# f28002x_mem_cfg_regs register map
Vendor: Texas Instruments
Peripheral module from a debugger description file (folder C2000).
Address unit: 16 bits
Registers are 32-bit, read-write, no defined reset value unless marked. A register's access mark holds for its fields unless they carry their own. Offsets are as the file gives them; lines under a group give offsets from that group; [hi:lo] are bit positions; {n}, {i} and the like mark numbered series; 'fields as' and 'values as' point back to an identical list; <NAME> marks a mode.

## MEM_CFG_REGS — MEM CFG Registers
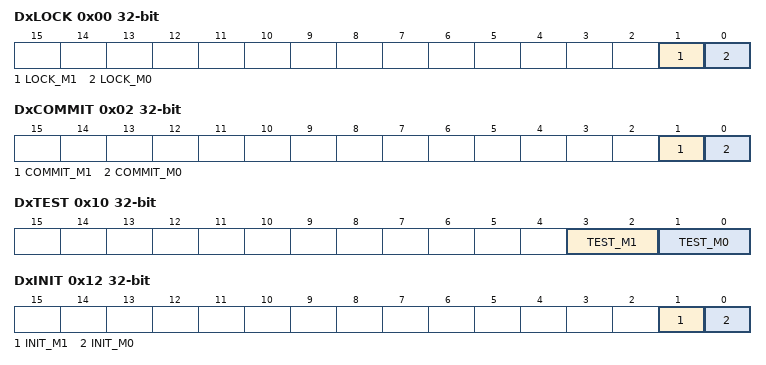
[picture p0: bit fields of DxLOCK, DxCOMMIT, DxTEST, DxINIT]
0x00 DxLOCK — Dedicated RAM Config Lock Register
  [1] LOCK_M1 — M1 RAM Lock bits
  [0] LOCK_M0 — M0 RAM Lock bits
0x02 DxCOMMIT — Dedicated RAM Config Lock Commit Register
  [1] COMMIT_M1 — M1 RAM Permanent Lock bits
  [0] COMMIT_M0 — M0 RAM Permanent Lock bits
0x10 DxTEST — Dedicated RAM TEST Register
  [3:2] TEST_M1 — Selects the different modes for M1 RAM
  [1:0] TEST_M0 — Selects the different modes for M0 RAM
0x12 DxINIT — Dedicated RAM Init Register
  [1] INIT_M1 — RAM Initialization control for M1 RAM.
  [0] INIT_M0 — RAM Initialization control for M0 RAM.
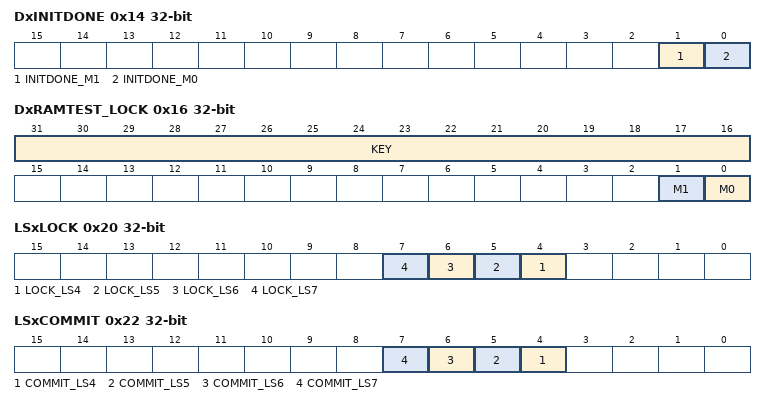
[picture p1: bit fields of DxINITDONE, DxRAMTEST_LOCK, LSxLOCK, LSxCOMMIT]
0x14 DxINITDONE ro — Dedicated RAM InitDone Status Register
  [1] INITDONE_M1 — RAM Initialization status for M1 RAM.
  [0] INITDONE_M0 — RAM Initialization status for M0 RAM.
0x16 DxRAMTEST_LOCK — Lock register to Dx RAM TEST registers
  [31:16] KEY — Key for writing DxRAMTEST_LOCK
  [1] M1 — DxTEST.TEST_M1 LOCK
  [0] M0 — DxTEST.TEST_M0 LOCK
0x20 LSxLOCK — Local Shared RAM Config Lock Register
  [n] LOCK_LS{n} (n=4..7) — LS{n} RAM Lock bits
0x22 LSxCOMMIT — Local Shared RAM Config Lock Commit Register
  [n] COMMIT_LS{n} (n=4..7) — LS{n} RAM Permanent Lock bits
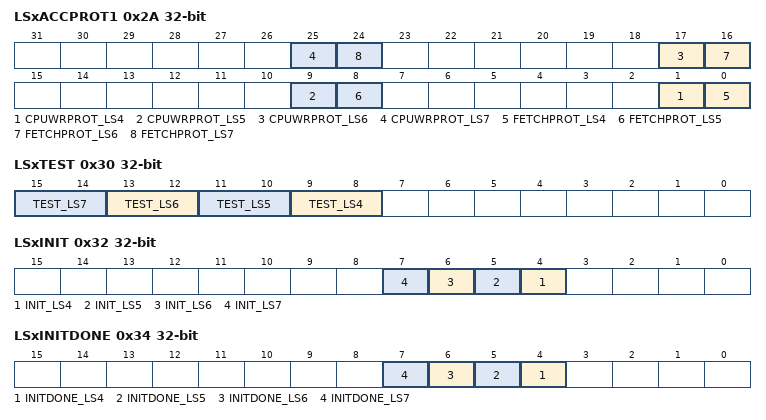
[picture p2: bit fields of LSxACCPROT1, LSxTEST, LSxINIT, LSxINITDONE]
0x2A LSxACCPROT1 — Local Shared RAM Config Register 1
  [8n-31] CPUWRPROT_LS{n} (n=4..7) — CPU WR Protection For LS{n} RAM
  [8n-32] FETCHPROT_LS{n} (n=4..7) — Fetch Protection For LS{n} RAM
0x30 LSxTEST — Local Shared RAM TEST Register
  [2n+1:2n] TEST_LS{n} (n=4..7) — Selects the different modes for LS{n} RAM
0x32 LSxINIT — Local Shared RAM Init Register
  [n] INIT_LS{n} (n=4..7) — RAM Initialization control for LS{n} RAM.
0x34 LSxINITDONE ro — Local Shared RAM InitDone Status Register
  [n] INITDONE_LS{n} (n=4..7) — RAM Initialization status for LS{n} RAM.
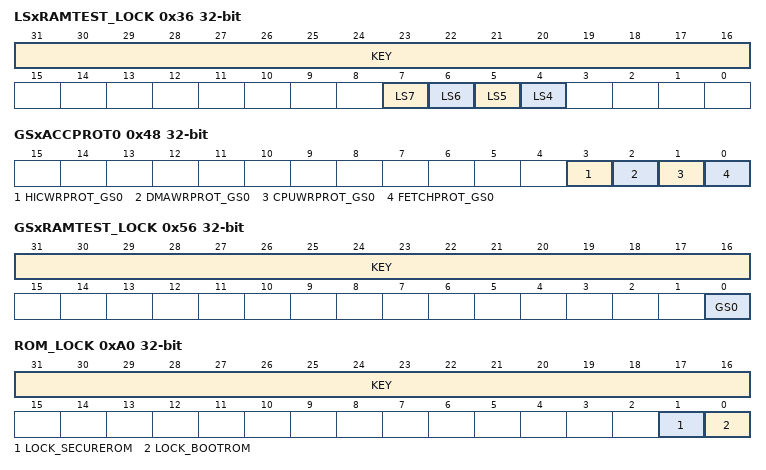
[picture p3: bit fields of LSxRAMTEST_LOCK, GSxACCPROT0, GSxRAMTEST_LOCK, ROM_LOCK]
0x36 LSxRAMTEST_LOCK — Lock register to LSx RAM TEST registers
  [31:16] KEY — KEY to enable write to lock
  [n] LS{n} (n=4..7) — LSxTEST.TEST_LS{n} LOCK
0x40 GSxLOCK — Global Shared RAM Config Lock Register
  [0] LOCK_GS0 — GS0 RAM Lock bits
0x42 GSxCOMMIT — Global Shared RAM Config Lock Commit Register
  [0] COMMIT_GS0 — GS0 RAM Permanent Lock bits
0x48 GSxACCPROT0 — Global Shared RAM Config Register 0
  [3] HICWRPROT_GS0 — HIC WR Protection For GS0 RAM
  [2] DMAWRPROT_GS0 — DMA WR Protection For GS0 RAM
  [1] CPUWRPROT_GS0 — CPU WR Protection For GS0 RAM
  [0] FETCHPROT_GS0 — Fetch Protection For GS0 RAM
0x50 GSxTEST — Global Shared RAM TEST Register
  [1:0] TEST_GS0 — Selects the different modes for GS0 RAM
0x52 GSxINIT — Global Shared RAM Init Register
  [0] INIT_GS0 — RAM Initialization control for GS0 RAM.
0x54 GSxINITDONE ro — Global Shared RAM InitDone Status Register
  [0] INITDONE_GS0 — RAM Initialization status for GS0 RAM.
0x56 GSxRAMTEST_LOCK — Lock register to GSx RAM TEST registers
  [31:16] KEY — KEY to enable write to lock
  [0] GS0 — GSxTEST.TEST_GS0 LOCK
0xA0 ROM_LOCK — ROM Config Lock Register
  [31:16] KEY — Key for writing ROM LOCK
  [1] LOCK_SECUREROM — SECUREROM Lock bits
  [0] LOCK_BOOTROM — BOOTROM Lock bits
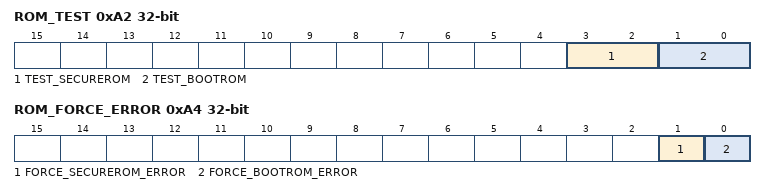
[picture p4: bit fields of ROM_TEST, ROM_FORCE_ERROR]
0xA2 ROM_TEST
  [3:2] TEST_SECUREROM — Selects the different modes for SECUREROM
  [1:0] TEST_BOOTROM — Selects the different modes for BOOTROM
0xA4 ROM_FORCE_ERROR
  [1] FORCE_SECUREROM_ERROR — Force SECUREROM Parity Error
  [0] FORCE_BOOTROM_ERROR — Force Bootrom Parity Error
